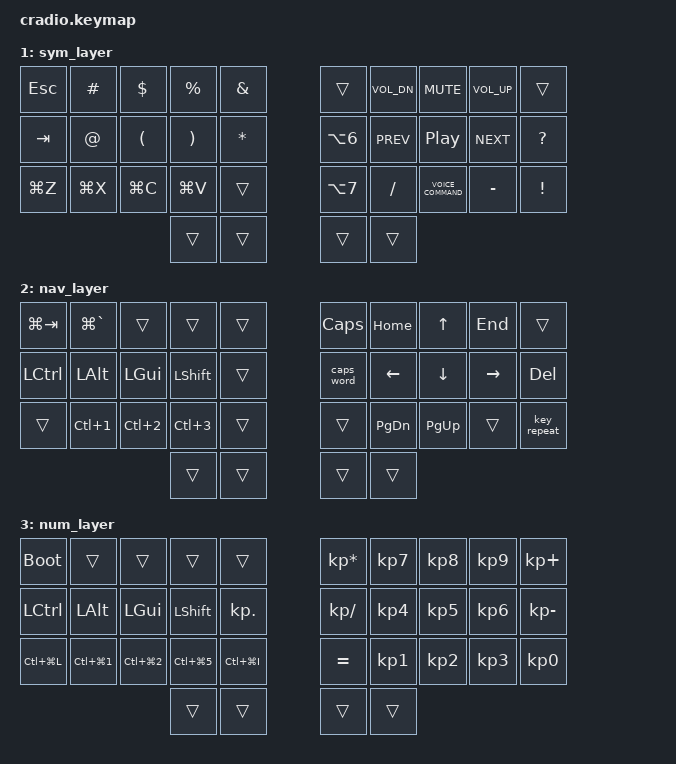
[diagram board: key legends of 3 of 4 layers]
// Copyright (c) 2022 The ZMK Contributors
// SPDX-License-Identifier: MIT

#include <behaviors.dtsi>
#include <dt-bindings/zmk/keys.h>
#include <dt-bindings/zmk/bt.h>

// Home row mods macro
#define HRML(k1,k2,k3,k4) &ht LCTRL k1  &ht LALT k2  &ht LGUI k3  &ht LSHFT k4
#define HRMR(k1,k2,k3,k4) &ht RSHFT k1  &ht RGUI k2  &ht RALT k3  &ht RCTRL k4

/ {
    behaviors {
        ht: hold_tap {
            compatible = "zmk,behavior-hold-tap";
            #binding-cells = <2>;
            flavor = "tap-preferred";
            tapping-term-ms = <220>;
            quick-tap-ms = <150>;
            require-prior-idle-ms = <100>;
            bindings = <&kp>, <&kp>;
        };
    };

//    conditional_layers {
//       compatible = "zmk,conditional-layers";
//         tri_layer {
//             if-layers = <1 2>;
//             then-layer = <3>;
//         };
//    };

    keymap {
        compatible = "zmk,keymap";
        default_layer {
            bindings = <
        //╭──────────┬──────────┬──────────┬──────────┬──────────╮   ╭──────────┬──────────┬──────────┬──────────┬──────────╮
        //│  Q       │  W       │  M       │  B       │  Z       │   │  J       │  F       │  O       │  U       │  ; :     │
            &kp Q      &kp W      &kp M      &kp B      &kp Z          &kp J      &kp F     &kp O       &kp U      &kp SEMI
        //├──────────┼──────────┼──────────┼──────────┼──────────┤   ├──────────┼──────────┼──────────┼──────────┼──────────┤
        //│  N       │  R       │  S       │  T       │  G       │   │  Y       │  H       │  E       │  I       │ ' "      │
        //   HRML(M,        S,         D,         F)     &kp G          &kp Y      HRMR(H,        E,         I,        SQT)        
             HRML(N,        R,         S,         T)     &kp G          &kp Y      HRMR(H,        E,         I,        A)
        //├──────────┼──────────┼──────────┼──────────┼──────────┤   ├──────────┼──────────┼──────────┼──────────┼──────────┤
        //│  X       │  L       │  C       │  D       │  V       │   │  K       │  P       │ , <      │ . >      │ ' "      │
        //  &kp Z      &kp X      &kp C      &kp V      &kp B          &kp N      &kp M      &kp COMMA  &kp DOT    &kp FSLH
            &kp X      &kp L      &kp C      &kp D      &kp V          &kp K      &kp P      &kp COMMA  &kp DOT    &kp SQT
        //╰──────────┴──────────┴──────────┼──────────┼──────────┤   ├──────────┼──────────┼──────────┴──────────┴──────────╯
                                            &lt 2 BSPC  &mo 3          &lt 3 ENTER  &lt 1 SPACE
        //                                 ╰──────────┴──────────╯   ╰──────────┴──────────╯
            >;
        };

        sym_layer {
            bindings = <
        //╭──────────┬──────────┬──────────┬──────────┬──────────╮   ╭──────────┬──────────┬──────────┬──────────┬──────────╮
        //│ ESC      │  #       │  $       │  %       │  &       │   │          │ VOL DN   │ MUTE     │ VOL UP   │          │
            &kp ESC    &kp HASH   &kp DLLR   &kp PRCNT  &kp AMPS       &trans     &kp C_VOL_DN  &kp C_MUTE  &kp C_VOL_UP  &trans
        //├──────────┼──────────┼──────────┼──────────┼──────────┤   ├──────────┼──────────┼──────────┼──────────┼──────────┤
        //│ TAB      │  @       │  (       │  )       │  *       │   │ SECTION  │ PREV     │ PP       │ NEXT     │          │
            &kp TAB    &kp AT     &kp LPAR   &kp RPAR   &kp STAR       &kp LA(N6) &kp C_PREV  &kp C_PP   &kp C_NEXT  &kp QMARK
        //├──────────┼──────────┼──────────┼──────────┼──────────┤   ├──────────┼──────────┼──────────┼──────────┼──────────┤
        //│ CMD-Z    │  CMD-X   │  CMD-C   │  CMD-V   │          │   │  PARA    │   /      │  VOICE   │ -        │          │
            &kp LG(Z)  &kp LG(X)  &kp LG(C)  &kp LG(V)   &trans         &kp LA(N7)  &kp SLASH  &kp C_VOICE_COMMAND  &kp MINUS  &kp EXCL
        //╰──────────┴──────────┴──────────┼──────────┼──────────┤   ├──────────┼──────────┼──────────┴──────────┴──────────╯
                                             &trans     &trans         &trans     &trans
        //                                 ╰──────────┴──────────╯   ╰──────────┴──────────╯
            >;
        };

        nav_layer {
            bindings = <
        //╭──────────┬──────────┬──────────┬──────────┬──────────╮   ╭──────────┬──────────┬──────────┬──────────┬──────────╮
        //│ SW APP   │  SW WIN  │          │          │          │   │  CAPS-L  │  HOME    │  UP      │  END     │
            &kp LG(TAB)  &kp LG(GRAVE)  &trans  &trans  &trans         &kp CAPSLOCK  &kp HOME  &kp UP   &kp END    &trans
        //├──────────┼──────────┼──────────┼──────────┼──────────┤   ├──────────┼──────────┼──────────┼──────────┼──────────┤
        //│          │          │          │          │          │   │  CAPS-W  │  LEFT    │  DOWN    │  RIGHT   │  DEL     │
            &kp LCTRL   &kp LALT  &kp LGUI   &kp LSHFT  &trans         &caps_word  &kp LEFT   &kp DOWN  &kp RIGHT  &kp DEL
        //├──────────┼──────────┼──────────┼──────────┼──────────┤   ├──────────┼──────────┼──────────┼──────────┼──────────┤
        //│          │ SPC 1    │  SPC 2   │  SPC 3   │          │   │          │  PG DN   │  PG UP   │          │          │
            &trans     &kp LC(N1)  &kp LC(N2)  &kp LC(N3)  &trans      &trans     &kp PG_DN  &kp PG_UP  &trans     &key_repeat
        //╰──────────┴──────────┴──────────┼──────────┼──────────┤   ├──────────┼──────────┼──────────┴──────────┴──────────╯
                                             &trans     &trans         &trans     &trans
        //                                 ╰──────────┴──────────╯   ╰──────────┴──────────╯
            >;
        };

        num_layer {
            bindings = <
        //╭──────────┬──────────┬──────────┬──────────┬──────────╮   ╭──────────┬──────────┬──────────┬──────────┬──────────╮
        //│BOOTLOADER│          │          │          │          │   │  MULT    │  7       │  8       │  9       │  PLUS    │
          &bootloader  &trans     &trans     &trans    &trans          &kp KP_MULTIPLY  &kp KP_N7  &kp KP_N8  &kp KP_N9  &kp KP_PLUS
        //├──────────┼──────────┼──────────┼──────────┼──────────┤   ├──────────┼──────────┼──────────┼──────────┼──────────┤
        //│          │          │          │          │ DOT      │   │  DIVIDE  │  4       │  5       │  6       │ MINUS    │
            &kp LCTRL  &kp LALT   &kp LGUI   &kp LSHFT  &kp KP_DOT    &kp KP_SLASH  &kp KP_N4  &kp KP_N5  &kp KP_N6  &kp KP_MINUS
        //├──────────┼──────────┼──────────┼──────────┼──────────┤   ├──────────┼──────────┼──────────┼──────────┼──────────┤
        //│ RECT-L   │ RECT-1   │ RECT-2   │ RECT-5   │ RECT-I   │   │  EQUAL   │  1       │  2       │  3       │  0       │
        //  &kp LC(LGUI(L))  &kp LC(LGUI(N1))  &kp LC(LGUI(N2))  &kp LC(LGUI(N5))  &kp LC(LGUI(I))  &kp EQUAL  &kp KP_N1  &kp KP_N2  &kp KP_N3     &kp KP_N0
            &kp LC(LG(L))  &kp LC(LG(N1))  &kp LC(LG(N2))  &kp LC(LG(N5))  &kp LC(LG(I))  &kp EQUAL  &kp KP_N1    &kp KP_N2  &kp KP_N3  &kp KP_N0
        //╰──────────┴──────────┴──────────┼──────────┼──────────┤   ├──────────┼──────────┼──────────┴──────────┴──────────╯
                                             &trans     &trans         &trans     &trans
        //                                 ╰──────────┴──────────╯   ╰──────────┴──────────╯
            >;
        };
    };
};
